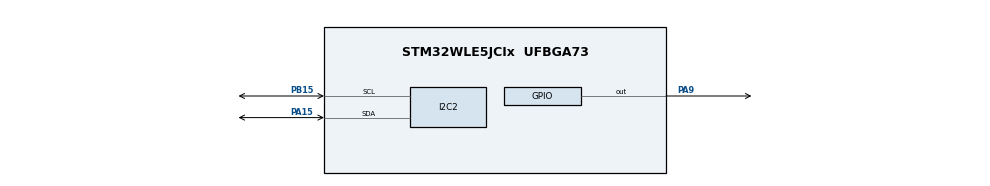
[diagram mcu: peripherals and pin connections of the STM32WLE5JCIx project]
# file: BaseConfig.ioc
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I2C2.Timing=0x00100D14
Mcu.Family=STM32WL
Mcu.Name=STM32WLE5JCIx
Mcu.Package=UFBGA73
NVIC.PriorityGroup=NVIC_PRIORITYGROUP_4
PA13.Mode=Serial_Wire
PA13.Signal=DEBUG_JTMS-SWDIO
PA14.Mode=Serial_Wire
PA14.Signal=DEBUG_JTCK-SWCLK
PA15.GPIO_Pu=GPIO_PULLUP
PA15.GPIO_Speed=GPIO_SPEED_FREQ_MEDIUM
PA15.Mode=I2C
PA15.Signal=I2C2_SDA
PA9.Signal=GPIO_Output
PB15.GPIO_Pu=GPIO_PULLUP
PB15.GPIO_Speed=GPIO_SPEED_FREQ_MEDIUM
PB15.Mode=I2C
PB15.Signal=I2C2_SCL
ProjectManager.HeapSize=0x200
ProjectManager.StackSize=0x400
ProjectManager.TargetToolchain=STM32CubeIDE
RCC.HSE_VALUE=8000000
RCC.HSI_VALUE=16000000
RCC.LSE_VALUE=32768
RCC.VCOOutputFreq_Value=32000000
board=custom

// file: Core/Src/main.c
/* USER CODE BEGIN Header */
/**
  ******************************************************************************
  * @file           : main.c
  * @brief          : Main program body
  ******************************************************************************
  * @attention
  *
  * Copyright (c) 2025 STMicroelectronics.
  * All rights reserved.
  *
  * This software is licensed under terms that can be found in the LICENSE file
  * in the root directory of this software component.
  * If no LICENSE file comes with this software, it is provided AS-IS.
  *
  ******************************************************************************
  */
/* USER CODE END Header */
#include "main.h"

/* USER CODE BEGIN Includes */
#include <stdbool.h>
#include <stdio.h>
#include <LM75ADP.h>
#include <sht40.h>
#include <bmp280.h>

//#define SHT40_READ_SERIAL      0x89
//#define SHT40_I2C_TIMEOUT 1000 /* 100 ms */
//#define SHT40_I2C_RESP_LEN 6

//static const uint8_t SHT40_I2C_ADDR = 0x44 << 1; // Use 8-bit address
//static const uint8_t REG_TEMP = 0x00;
/* USER CODE END Includes */

/* USER CODE BEGIN PD */

#define FIVE_SECONDS_MS 5000
/* USER CODE END PD */

I2C_HandleTypeDef hi2c2;

/* USER CODE BEGIN PV */
BMP280_HandleTypedef bmp280;

float pressure, temperature, humidity;

/* USER CODE END PV */

void SystemClock_Config(void);
static void MX_GPIO_Init(void);
static void MX_I2C2_Init(void);

int main(void)
{

  /* USER CODE BEGIN 1 */
	//HAL_StatusTypeDef ret;
	//uint8_t buf[12];
	//int16_t val;
	//float temp_c;
  /* USER CODE END 1 */

  /* MCU Configuration--------------------------------------------------------*/

  /* Reset of all peripherals, Initializes the Flash interface and the Systick. */
  HAL_Init();

  /* Configure the system clock */
  SystemClock_Config();

  /* Initialize all configured peripherals */
  MX_GPIO_Init();
  MX_I2C2_Init();
  /* USER CODE BEGIN 2 */
  HAL_GPIO_WritePin(GPIOA,GPIO_PIN_9,GPIO_PIN_SET);
  //HAL_GPIO_WritePin(GPIOA,GPIO_PIN_9,GPIO_PIN_RESET);
  Sensor_Data sData;
  SHT40_Measurement measurement;
  LM75_Data result;

  if (LM75ADP_conf(&hi2c2, LM75ADP_I2C_TIMEOUT) != HAL_OK) {
	  sData.Okay = false;
  }

  uint32_t sht40_serial;
  if (SHT40_ReadSerial(&hi2c2, &sht40_serial) != HAL_OK ) {
	  sData.Okay = false;
  }

  bmp280_init_default_params(&bmp280.params);
  bmp280.addr = BMP280_I2C_ADDRESS_0;
  bmp280.i2c = &hi2c2;
  int try_count = 0;

  while (!bmp280_init(&bmp280, &bmp280.params) && sData.Okay) {
	  sData.Okay = (try_count++ < 5 );
	  HAL_Delay(FIVE_SECONDS_MS);
  }
  //bool bme280p = bmp280.id == BME280_CHIP_ID;

  HAL_Delay(FIVE_SECONDS_MS);
  /* USER CODE END 2 */

  /* Infinite loop */
  /* USER CODE BEGIN WHILE */

  // Set PA9 to HIGH

  while (sData.Okay)
  {
	  // Temporary code will move to Lora network just need to import and get it working .... hopefully

	  if (LM75ADP_read(&hi2c2, &result, LM75ADP_I2C_TIMEOUT) != HAL_OK) {
		sData.Okay = false;
	  } else {
		sData.LM75ADP_f_temperature = result.f_temp;
	  }

	  if( SHT40_Measure(&hi2c2, &measurement, MED_PRECISION) != HAL_OK ) {
		sData.Okay = false;
	  } else {
		sData.sht40_f_relhumidity = measurement.rel_humidity;
		sData.sht40_f_temperature = measurement.temperature;
	  }

	  if (!bmp280_read_float(&bmp280, &temperature, &pressure, &humidity)) {
		sData.Okay = false;
	  } else {
		sData.BMP280_f_humidity = humidity;
		sData.BMP280_f_pressure = pressure;
		sData.BMP280_f_temperature = temperature;
	  }

	  HAL_Delay(FIVE_SECONDS_MS);

    /* USER CODE END WHILE */

  }
}

void SystemClock_Config(void)
{
  RCC_OscInitTypeDef RCC_OscInitStruct = {0};
  RCC_ClkInitTypeDef RCC_ClkInitStruct = {0};

  /** Configure the main internal regulator output voltage
  */
  __HAL_PWR_VOLTAGESCALING_CONFIG(PWR_REGULATOR_VOLTAGE_SCALE2);

  /** Initializes the CPU, AHB and APB buses clocks
  */
  RCC_OscInitStruct.OscillatorType = RCC_OSCILLATORTYPE_MSI;
  RCC_OscInitStruct.MSIState = RCC_MSI_ON;
  RCC_OscInitStruct.MSICalibrationValue = RCC_MSICALIBRATION_DEFAULT;
  RCC_OscInitStruct.MSIClockRange = RCC_MSIRANGE_6;
  RCC_OscInitStruct.PLL.PLLState = RCC_PLL_NONE;
  if (HAL_RCC_OscConfig(&RCC_OscInitStruct) != HAL_OK)
  {
    Error_Handler();
  }

  /** Configure the SYSCLKSource, HCLK, PCLK1 and PCLK2 clocks dividers
  */
  RCC_ClkInitStruct.ClockType = RCC_CLOCKTYPE_HCLK3|RCC_CLOCKTYPE_HCLK
                              |RCC_CLOCKTYPE_SYSCLK|RCC_CLOCKTYPE_PCLK1
                              |RCC_CLOCKTYPE_PCLK2;
  RCC_ClkInitStruct.SYSCLKSource = RCC_SYSCLKSOURCE_MSI;
  RCC_ClkInitStruct.AHBCLKDivider = RCC_SYSCLK_DIV1;
  RCC_ClkInitStruct.APB1CLKDivider = RCC_HCLK_DIV1;
  RCC_ClkInitStruct.APB2CLKDivider = RCC_HCLK_DIV1;
  RCC_ClkInitStruct.AHBCLK3Divider = RCC_SYSCLK_DIV1;

  if (HAL_RCC_ClockConfig(&RCC_ClkInitStruct, FLASH_LATENCY_0) != HAL_OK)
  {
    Error_Handler();
  }
}

static void MX_I2C2_Init(void)
{

  hi2c2.Instance = I2C2;
  hi2c2.Init.Timing = 0x00100D14;
  hi2c2.Init.OwnAddress1 = 0;
  hi2c2.Init.AddressingMode = I2C_ADDRESSINGMODE_7BIT;
  hi2c2.Init.DualAddressMode = I2C_DUALADDRESS_DISABLE;
  hi2c2.Init.OwnAddress2 = 0;
  hi2c2.Init.OwnAddress2Masks = I2C_OA2_NOMASK;
  hi2c2.Init.GeneralCallMode = I2C_GENERALCALL_DISABLE;
  hi2c2.Init.NoStretchMode = I2C_NOSTRETCH_DISABLE;
  if (HAL_I2C_Init(&hi2c2) != HAL_OK)
  {
    Error_Handler();
  }

  /** Configure Analogue filter
  */
  if (HAL_I2CEx_ConfigAnalogFilter(&hi2c2, I2C_ANALOGFILTER_ENABLE) != HAL_OK)
  {
    Error_Handler();
  }

  /** Configure Digital filter
  */
  if (HAL_I2CEx_ConfigDigitalFilter(&hi2c2, 0) != HAL_OK)
  {
    Error_Handler();
  }

}

static void MX_GPIO_Init(void)
{
  GPIO_InitTypeDef GPIO_InitStruct = {0};

  /* GPIO Ports Clock Enable */
  __HAL_RCC_GPIOA_CLK_ENABLE();
  __HAL_RCC_GPIOB_CLK_ENABLE();

  /*Configure GPIO pin Output Level */
  HAL_GPIO_WritePin(GPIOA, GPIO_PIN_9, GPIO_PIN_RESET);

  /*Configure GPIO pin : PA9 */
  GPIO_InitStruct.Pin = GPIO_PIN_9;
  GPIO_InitStruct.Mode = GPIO_MODE_OUTPUT_PP;
  GPIO_InitStruct.Pull = GPIO_NOPULL;
  GPIO_InitStruct.Speed = GPIO_SPEED_FREQ_LOW;
  HAL_GPIO_Init(GPIOA, &GPIO_InitStruct);

}

void Error_Handler(void)
{
  __disable_irq();
  while (1)
  {
  }
}
